AUTOSAR XML (schema 4-2-2)
package /AUTOLIV/SoftwareComponents/DIA
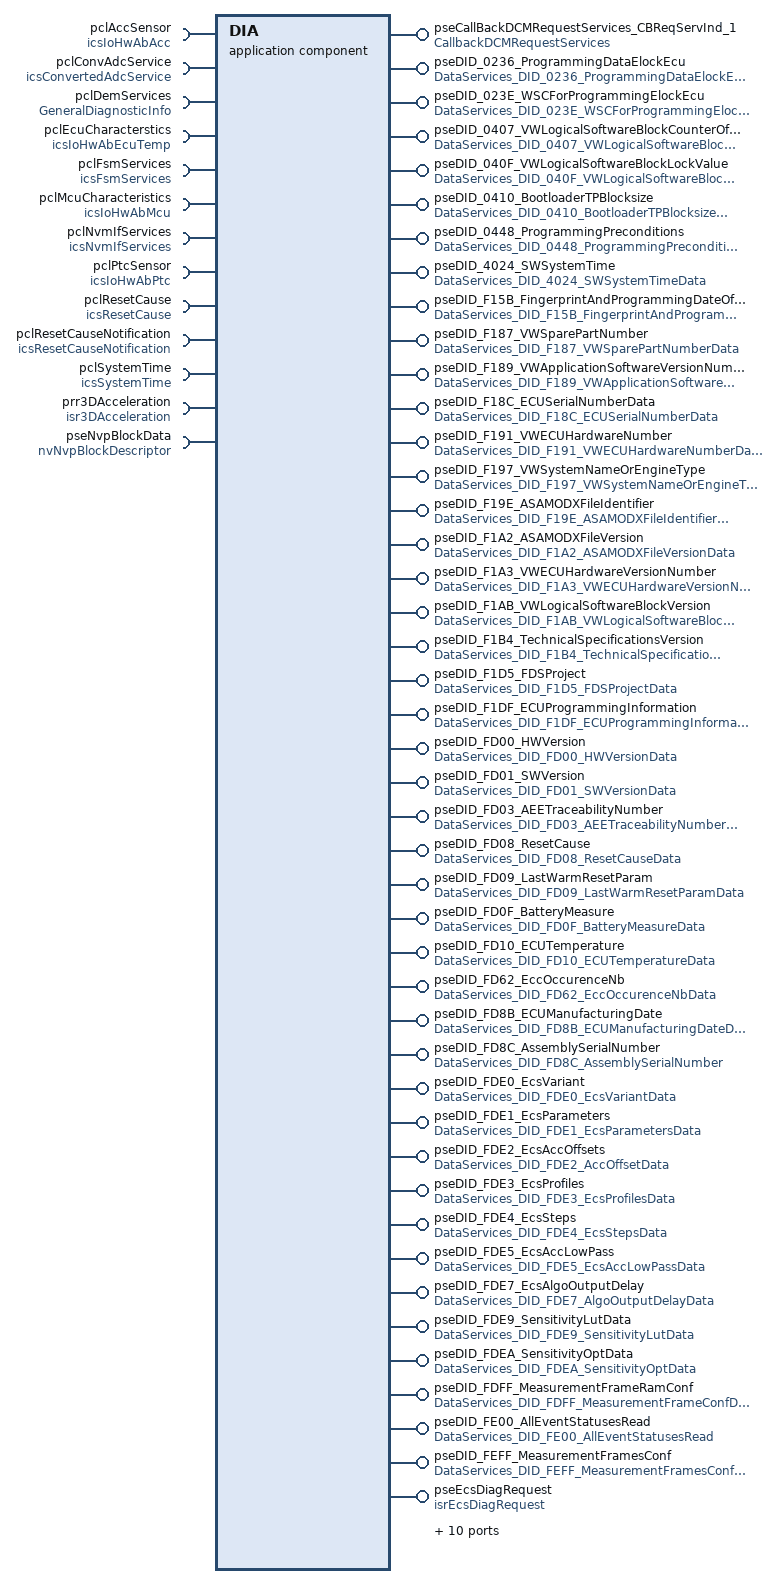
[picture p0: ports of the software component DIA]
  application sw component type DIA: category=SWC
    12 x require port:
      pclAccSensor: client-com-spec=GetTemperature, required-interface=icsIoHwAbAcc  # # Architecture Element ID ARCH_SW_DIA_pclAccSensor # Description - Interface shall be used to get the {temperature of the accelerometer in ℃}. # Data Flow ## Inputs: ## Outputs - {temperature of the accelerometer in ℃} # Linked Runnable - DIA_runRidF796_EcuTempCalibration # Traceability
      pclConvAdcService: client-com-spec=getMeasure, required-interface=icsConvertedAdcService  # # Architecture Element ID ARCH_SW_DIA_pclConvAdcService # Description - Interface shall be used to get {current value in mV} and {Mcu temperature in ℃}. # Data Flow ## Inputs: ## Outputs - {current value in mV} - {Mcu temperature in ℃} # Linked Runnable - DIA_runDid_FD0F_BatteryMeasureRead - DIA_run_DidFD10_ECUTemperatureRead # Traceability
      pclDemServices: required-interface=GeneralDiagnosticInfo  # # Architecture Element ID ARCH_SW_DIA_pclDemServices_GetEventStatus # Description - Interface used to get {the current extended event status} of a specific {event ID}. # Data Flow ## Inputs: - {event ID} ## Outputs - {the current extended event status} # Linked Runnable - DIA_runDidFE00_AllEventStatusesRead - DIA_runRid0203_CheckProgrammingPreconditions # Traceability # Architecture Element ID ARCH_SW_DIA_pclDemServices_GetEventFailed
        required-com-specs:
          GetEventStatus
          GetEventFailed
          GetEventTested
          GetDTCOfEvent
          GetFaultDetectionCounter
          GetEventFreezeFrameData
          GetEventExtendedDataRecord
          GetDebouncingOfEvent
          GetEventExtendedDataRecordEx
          GetEventFreezeFrameDataEx
      pclEcuCharacterstics: client-com-spec=GetTemperature, required-interface=icsIoHwAbEcuTemp  # # Architecture Element ID ARCH_SW_DIA_pclEcuCharacteristics # Description - Interface used to get the {Ecu temperature in ℃}. # Data Flow ## Inputs: ## Outputs - {Ecu temperature in ℃}s # Linked Runnable - DIA_run_DidFD10_ECUTemperatureRead # Traceability
      pclFsmServices: required-com-specs=[calculateProfileTimeout, getUnlockTimeoutPeriod], required-interface=icsFsmServices  # # Architecture Element ID ARCH_SW_DIA_pclFsmServices # Description - Interface shall be used to return {unlocking timeout period} of a specific {profile index}. # Data Flow ## Inputs: - {profile index} ## Outputs - {unlocking timeout period} # Linked Runnable - DIA_runDidFDE3_EcsProfilesWrite - DIA_runDidFDE4_EcsStepsWrite # Traceability
      pclMcuCharacteristics: client-com-spec=GetTemperature, required-interface=icsIoHwAbMcu  # # Architecture Element ID ARCH_SW_DIA_pclMcuCharacteristics # Description - Interface used to get the {Mcu temperature in ℃}. # Data Flow ## Inputs: ## Outputs - {Mcu temperature in ℃} # Linked Runnable - CIL_runManageMF - DIA_runRidF796_EcuTempCalibration # Traceability
      pclNvmIfServices: required-interface=icsNvmIfServices  # # Architecture Element ID ARCH_SW_DIA_pclNvmIfServices_GetNvmBlockLength # Description - Interface shall be used on event to know the {block length} of a specific {block ID}. # Data Flow ## Inputs: - {block ID} ## Outputs - {block length} # Linked Runnable - DIA_runDidFD00_HWVersionRead - DIA_runDidFEFF_MeasurementFramesConfRead - DIA_runDidFD03_AEETraceabilityNumberRead - DIA_runDidFD62_EccOccurenceNbRead - DIA_runDidFDE1_EcsParametersRead - DIA_runDidFDE2_EcsAccOffsetsRead - DIA_runDidFDE3_EcsProfilesRead - DIA_runDidFDE4_EcsStepsRead - DIA_runDidFDE5_EcsAccLowPassRead - DIA_runDIDFDE7_EcsAlgoOutputDelayRead - DIA_runDidFDE9_EcsSensitivityLutRead - DIA_runDidF187_VWSparePartNumberRead - DIA_runDidF189_VWApplicationSoftwareVersionNumberRead - DIA_runDidF191_VWECUHardwareNumberRead - DIA_runDidF197_VWSystemNameOrEngineTypeRead - DIA_runDidF1A2_ASAMODXFileVersionRead - DIA_runDidF1A3_VWECUHardwareVersionNumberRead - DIA_runDidF18C_ECUSerialNumberRead - DIA_runDidF1AB_VWLogicalSoftwareBlockVersionRead - DIA_runDidF19E_ASAMODXFileIdentifierRead - DIA_runDidFDE2_EcsAccOffsetsWrite - DIA_runDidFDE3_EcsProfilesWrite - DIA_runDidFDE4_EcsStepsWrite - DIA_runDidFDE9_EcsSensitivityLutWrite - DIA_runDidFDEA_EcsSensitivityOptWrite - DIA_runDidF189_VWApplicationSoftwareVersionNumberWrite - DIA_runDidF191_VWECUHardwareNumberWrite - DIA_runDidF197_VWSystemNameOrEngineTypeWrite - DIA_runDidF19E_ASAMODXFileIdentifierWrite - DIA_runDidF1A2_ASAMODXFileVersionWrite - DIA_runDidF18C_ECUSerialNumberWrite - DIA_runDidF1A3_VWECUHardwareVersionNumberWrite # Traceability # Architecture Element ID ARCH_SW_DIA_pclNvmIfServices_SetRamBlockStatus # Description - Interface shall be used to set the {status of a RAM block} of a specific {block ID}. # Data Flow ## Inputs: - {block ID} ## Outputs - {status of a RAM block} # Linked Runnable - DIA_runRidF796_EcuTempCalibration # Traceability # Architecture Element ID ARCH_SW_DIA_pclNvmIfServices_WriteNvmBlock # Description - Interface shall be used to write an Nvm block of a specific {block ID}. # Data Flow ## Inputs: - {block ID} ## Outputs - {Block Changed} # Linked Runnable - DIA_ManageNVPBlockWriting # Traceability # Architecture Element ID ARCH_SW_DIA_pclNvmIfServices_GetNvmBlockStatus # Description - Interface shall be used to set the {status of block} of a specific {block ID}. # Data Flow ## Inputs: - {block ID} ## Outputs - {status of block} # Linked Runnable - DIA_ManageNVPBlockWriting # Traceability
        required-com-specs:
          GetNvmBlockLength
          GetNvmBlockStatus
          ReadBlockByAddress
          RestorePRAMBlockDefaults
          SetRamBlockStatus
          WriteBlockByAddress
          WriteNvmBlock
      pclPtcSensor: client-com-spec=GetTemperature, required-interface=icsIoHwAbPtc  # # Architecture Element ID ARCH_SW_DIA_pclPtcSensor # Description - Interface used to get the {temperature of the resistor sensor in ℃}. # Data Flow ## Inputs: ## Outputs - {temperature of the resistor sensor in ℃} # Linked Runnable - DIA_runRidF796_EcuTempCalibration # Traceability
      pclResetCause: client-com-spec=GetResetCause, required-interface=icsResetCause  # # Architecture Element ID ARCH_SW_DIA_pclResetCause # Description - Interface shall be used to read the {last reset cause}. # Data Flow ## Inputs: ## Outputs - {last reset cause} # Linked Runnable - DIA_runDidFD08_ResetCauseRead # Traceability
      pclResetCauseNotification: client-com-spec=NotifyResetCause, required-interface=icsResetCauseNotification  # # Architecture Element ID ARCH_SW_DIA_pclResetCauseNotification # Description - Interface shall be used to notify DIA about the {reset cause} from RCM. # Data Flow ## Inputs: ## Outputs - {reset cause} # Linked Runnable - DIA_runDidFD08_ResetCauseRead # Traceability
      pclSystemTime: client-com-spec=ReadAbsoluteSystemTime, required-interface=icsSystemTime  # # Architecture Element ID ARCH_SW_DIA_pclSystemTime_ReadAbsoluteSystemTime # Description - Interface shall be used to read {absolute system time}. - {absolute system time} shall have 4 bytes of data + 1 byte reserved. # Data Flow ## Inputs: ## Outputs - {absolute system time} # Linked Runnable - DIA_runDid4024_SWSystemTimeRead # Traceability
      prr3DAcceleration: nonqueued-receiver-com-spec{data-element=st3DAccel, init-value=fields=[0, 0, 0]}, required-interface=isr3DAcceleration  # # Architecture Element ID ARCH_SW_prr3DAcceleration # Description - Interface shall be used to get {raw acceleration in G to CAN}. # Data Flow ## Inputs: ## Outputs - {raw acceleration in G to CAN} # Linked Runnable - DIA_runRidF794_AccCalibStart # Traceability
    44 x provide port:
      pseCallBackDCMRequestServices_CBReqServInd_1: provided-com-specs=[{operation=StartProtocol, queue-length=1}, {operation=StopProtocol, queue-length=1}], provided-interface=CallbackDCMRequestServices  # # Architecture Element ID ARCH_SW_DIA_pseCallBackDCMRequestServices_CBReqServInd_1 # Description - Interface shall be used to ask about prioritization of Diagnsotic Protocols to the Application. # Data Flow ## Inputs: - {protocol ID} ## Outputs # Linked Runnable - DIA_runCallBackDCMRequestServices_CBReqServInd_1_StartProtocol - DIA_runRte_Call_Dcm_CallBackDCMRequestServices_CBReqServInd_1_StopProtocol # Traceability
      pseDID_0236_ProgrammingDataElockEcu: provided-com-specs=[{operation=ReadData, queue-length=1}, {operation=WriteData, queue-length=1}], provided-interface=DataServices_DID_0236_ProgrammingDataElockEcuData  # # Architecture Element ID ARCH_SW_DIA_pseDID_0236_ProgrammingDataElockEcu_ReadData # Description - Interface shall be used to read {ECS parameters} from NVM and to save it in the {diagnostic buffer}. - The data content shall have 58 bytes ({ECS parameters} shall have 33 bytes + 26 bytes reserved). # Data Flow ## Inputs: - {ECS parameters} ## Outputs - {diagnostic buffer} # Linked Runnable - DIA_run_Did0236_ProgrammingDataElockEcuRead # Traceability DOM_eCS_TF_E_2130;DOM_eCS_TF_E_2133;DOM_eCS_TF_E_2134;DOM_eCS_TF_E_2135;DOM_eCS_TF_E_2136;DOM_eCS_TF_E_2137;DOM_eCS_TF_E_2137;DOM_eCS_TF_E_2138;DOM_eCS_TF_E_2139;DOM_eCS_TF_E_2140;DOM_eCS_TF_E_2141;DOM_eCS_TF_E_2142;DOM_eCS_TF_E_2143;DOM_eCS_TF_E_2144;DOM_eCS_TF_E_2145;DOM_eCS_TF_E_2146;DOM_eCS_TF_E_2147;DOM_eCS_TF_E_2148;DOM_eCS_TF_E_2149;DOM_eCS_TF_E_2150;DOM_eCS_TF_E_2151;DOM_eCS_TF_E_2152; DOM_eCS_TF_E_2153;DOM_eCS_TF_E_2154 # Architecture Element ID ARCH_SW_DIA_pseDID_0236_ProgrammingDataElockEcu_WriteData # Description - Interface shall be used to write the {diagnostic buffer} value in the NVP variables which store the {ECS parameters}. - The data content shall have 58 bytes ({ECS parameters} shall have 33 bytes + 26 bytes reserved). - Interface shall return {ErrorCode} 0x72 if the write operation failed. # Data Flow ## Inputs: - {diagnostic buffer} ## Outputs - {ECS parameters} # Linked Runnable - DIA_run_Did0236_ProgrammingDataElockEcuWrite # Traceability DOM_eCS_TF_E_2160;DOM_eCS_TF_E_2164;DOM_eCS_TF_E_2182;DOM_eCS_TF_E_2183;DOM_eCS_TF_E_2184;DOM_eCS_TF_E_2185;DOM_eCS_TF_E_2186;DOM_eCS_TF_E_2187;DOM_eCS_TF_E_2188;DOM_eCS_TF_E_2189;DOM_eCS_TF_E_2190;DOM_eCS_TF_E_2191;DOM_eCS_TF_E_2192;DOM_eCS_TF_E_2193;DOM_eCS_TF_E_2194;DOM_eCS_TF_E_2195;DOM_eCS_TF_E_2196;DOM_eCS_TF_E_2197;DOM_eCS_TF_E_2198;DOM_eCS_TF_E_2199;DOM_eCS_TF_E_2200;DOM_eCS_TF_E_2201;DOM_eCS_TF_E_2202;DOM_eCS_TF_E_2168
      pseDID_023E_WSCForProgrammingElockEcu: provided-com-specs=[{operation=ReadData, queue-length=1}, {operation=WriteData, queue-length=1}], provided-interface=DataServices_DID_023E_WSCForProgrammingElockEcuData  # # Architecture Element ID ARCH_SW_DIA_pseDID_023E_WSCForProgrammingElockEcu_ReadData # Description - Interface shall be used to read {ECS variant} from NVM and to save it in the {diagnostic buffer}. - The data content shall have 6 bytes ({ECS variant} shall have 4 bytes + 2 bytes reserved). # Data Flow ## Inputs: - {ECS variant} ## Outputs - {diagnostic buffer} # Linked Runnable - DIA_run_Did023E_WSCForProgrammingElockEcuRead # Traceability DOM_eCS_TF_E_2117;DOM_eCS_TF_E_2155 # Architecture Element ID ARCH_SW_DIA_pseDID_023E_WSCForProgrammingElockEcu_WriteData # Description - Interface shall be used to write the {diagnostic buffer} value in the NVP variable which stores the {ECS variant}. - The data content shall have 6 bytes ({ECS variant} shall have 4 bytes + 2 bytes reserved). - Interface shall return {ErrorCode} 0x72 if the write operation failed. # Data Flow ## Inputs: - {diagnostic buffer} ## Outputs - {ECS variant} # Linked Runnable - DIA_run_Did023E_WSCForProgrammingElockEcuWrite # Traceability DOM_eCS_TF_E_2176;DOM_eCS_TF_E_2177;DOM_eCS_TF_E_2181
      pseDID_0407_VWLogicalSoftwareBlockCounterOfProgrammingAttempts: server-com-spec{operation=ReadData, queue-length=1}, provided-interface=DataServices_DID_0407_VWLogicalSoftwareBlockCounterOfProgrammingAttemptsData  # # Architecture Element ID ARCH_SW_DIA_pseDID_0407_VWLogicalSoftwareBlockCounterOfProgrammingAttempts # Description - Interface shall be used to read {Ecu serial number} from NVM and to save it in the {diagnostic buffer}. # Data Flow ## Inputs: - {Ecu serial number} ## Outputs - {diagnostic buffer} # Linked Runnable - DIA_runDid0407_VWLogicalSoftwareBlockCounterOfProgrammingAttemptsRead # Traceability DOM_eCS_TF_E_1457; DOM_eCS_TF_E_1463; DOM_eCS_TF_E_1464
      pseDID_040F_VWLogicalSoftwareBlockLockValue: server-com-spec{operation=ReadData, queue-length=1}, provided-interface=DataServices_DID_040F_VWLogicalSoftwareBlockLockValueData  # # Architecture Element ID ARCH_SW_DIA_pseDID_040F_VWLogicalSoftwareBlockLockValue # Description - Interface shall be used to read {VW Logical Software Block Lock} value and to save it in the {diagnostic buffer}. - {VW Logical Software Block Lock} shall have 6 bytes. # Data Flow ## Inputs: - {VW Logical Software Block Lock} ## Outputs - {diagnostic buffer} # Linked Runnable - DIA_runDid040F_VWLogicalSoftwareBlockLockValueRead # Traceability DOM_eCS_TF_E_128; DOM_eCS_TF_E_1473; DOM_eCS_TF_E_1474; DOM_eCS_TF_E_1475
      pseDID_0410_BootloaderTPBlocksize: provided-com-specs=[{operation=ReadData, queue-length=1}, {operation=WriteData, queue-length=1}], provided-interface=DataServices_DID_0410_BootloaderTPBlocksizeData  # # Architecture Element ID ARCH_SW_DIA_pseDID_0410_BootloaderTPBlocksize_ReadData # Description - Interface shall be used to read {Bootloader TP block size} value and to save it in the {diagnostic buffer}. - {Bootloader TP block size} shall have 1 byte. # Data Flow ## Inputs: - {Bootloader TP block size} ## Outputs - {diagnostic buffer} # Linked Runnable - DIA_runDid0410_BootloaderTPBlocksizeRead # Traceability DOM_eCS_TF_E_128;DOM_eCS_TF_E_1492;DOM_eCS_TF_E_1946 # Architecture Element ID ARCH_SW_DIA_pseDID_0410_BootloaderTPBlocksize_WriteData # Description - Interface shall be used to write the {diagnostic buffer} value in the variable which stores the {Bootloader TP block size}. - {Bootloader TP block size} shall have 1 byte. # Data Flow ## Inputs: - {diagnostic buffer} ## Outputs - {Bootloader TP block size} # Linked Runnable - DIA_runDid0410_BootloaderTPBlocksizeWrite # Traceability DOM_eCS_TF_E_633; DOM_eCS_TF_E_635
      pseDID_0448_ProgrammingPreconditions: server-com-spec{operation=ReadData, queue-length=1}, provided-interface=DataServices_DID_0448_ProgrammingPreconditionsData  # # Architecture Element ID ARCH_SW_DIA_pseDID_0448_ProgrammingPreconditions # Description - Interface shall be used to read the {programming preconditions} value and to save it in the {diagnostic buffer}. # Data Flow ## Inputs: - {programming preconditions} ## Outputs - {diagnostic buffer} # Linked Runnable - DIA_runDid0448_ProgrammingPreconditionsRead # Traceability DOM_eCS_TF_E_1501;DOM_eCS_TF_E_1505;DOM_eCS_TF_E_1506;DOM_eCS_TF_E_1507;DOM_eCS_TF_E_1509
      pseDID_4024_SWSystemTime: server-com-spec{operation=ReadData, queue-length=1}, provided-interface=DataServices_DID_4024_SWSystemTimeData  # # Architecture Element ID ARCH_SW_DIA_pseDID_4024_SWSystemTime # Description - Interface shall be used to read the {absolute system time} value and to save it in the {diagnostic buffer}. - {absolute system time} shall have 5 bytes (4 bytes of data + 1 byte reserved). # Data Flow ## Inputs: - {absolute system time} ## Outputs - {diagnostic buffer} # Linked Runnable - DIA_runDid4024_SWSystemTimeRead # Traceability DOM_eCS_TF_E_183;DOM_eCS_TF_E_1520;DOM_eCS_TF_E_1524;DOM_eCS_TF_E_1525;DOM_eCS_TF_E_1527
      pseDID_F15B_FingerprintAndProgrammingDateOfLogicalSoftwareBlocks: server-com-spec{operation=ReadData, queue-length=1}, provided-interface=DataServices_DID_F15B_FingerprintAndProgrammingDateOfLogicalSoftwareBlocksData  # # Architecture Element ID ARCH_SW_DIA_pseDID_F15B_FingerprintAndProgrammingDateOfLogicalSoftwareBlocks # Description - Interface shall be used to read the {fingerprint and programming date of logical SW blocks} from NVM and to save it in the {diagnostic buffer}. - {fingerprint and programming date of logical SW blocks} shall have 30 bytes. # Data Flow ## Inputs: - {fingerprint and programming date of logical SW blocks} ## Outputs - {diagnostic buffer} # Linked Runnable - DIA_runDidF15B_FingerprintAndProgrammingDateOfLogicalSoftwareBlocksRead # Traceability
      pseDID_F187_VWSparePartNumber: provided-com-specs=[{operation=ReadData, queue-length=1}, {operation=WriteData, queue-length=1}], provided-interface=DataServices_DID_F187_VWSparePartNumberData  # # Architecture Element ID ARCH_SW_DIA_pseDID_F187_VWSparePartNumber_ReadData # Description - Interface shall be used to read {Spare Part Number} from NVM and to save it in the {diagnostic buffer}. - {Spare Part Number} shall have 11 bytes. # Data Flow ## Inputs: - {Spare Part Number} ## Outputs - {diagnostic buffer} # Linked Runnable - DIA_runDidF187_VWSparePartNumberRead # Traceability DOM_eCS_TF_E_1548;DOM_eCS_TF_E_1552 # Architecture Element ID ARCH_SW_DIA_pseDID_F187_VWSparePartNumber_WriteData # Description - Interface shall be used to write the {diagnostic buffer} value in the NVP variable which stores the {Spare Part Number}. - Interface shall return {ErrorCode} 0x22 if Ecu is locked. - Interface shall return {ErrorCode} 0x72 if the write operation failed. - Interface shall return {ErrorCode} 0x31 if the written values are not in ASCII codes interval. - {Spare Part Number} shall have 11 bytes. # Data Flow ## Inputs: - {diagnostic buffer} ## Outputs - {Spare Part Number} # Linked Runnable - DIA_runDidF187_VWSparePartNumberWrite # Traceability DOM_eCS_TF_E_1709;DOM_eCS_TF_E_1906;DOM_eCS_TF_E_1710;DOM_eCS_TF_E_1951;DOM_eCS_TF_E_1713;DOM_eCS_TF_E_1950
      pseDID_F189_VWApplicationSoftwareVersionNumber: provided-com-specs=[{operation=ReadData, queue-length=1}, {operation=WriteData, queue-length=1}], provided-interface=DataServices_DID_F189_VWApplicationSoftwareVersionNumberData  # # Architecture Element ID ARCH_SW_DIA_pseDID_F189_VWApplicationSoftwareVersionNumber_ReadData # Description - Interface shall be used to read {VW Application SW Version Number} from NVM and to save it in the {diagnostic buffer}. - {VW Application SW Version Number} shall have 4 bytes. # Data Flow ## Inputs: - {VW Application SW Version Number} ## Outputs - {diagnostic buffer} # Linked Runnable - DIA_runDidF189_VWApplicationSoftwareVersionNumberRead # Traceability DOM_eCS_TF_E_128;DOM_eCS_TF_E_115;DOM_eCS_TF_E_1575 # Architecture Element ID ARCH_SW_DIA_pseDID_F189_VWApplicationSoftwareVersionNumber_WriteData # Description - Interface shall be used to write the {diagnostic buffer} value in the NVP variable which stores the {VW Application SW Version Number}. - Interface shall return {ErrorCode} 0x22 if Ecu is locked. - Interface shall return {ErrorCode} 0x72 if the write operation failed. - {VW Application SW Version Number} shall have 4 bytes. # Data Flow ## Inputs: - {diagnostic buffer} ## Outputs - {VW Application SW Version Number} - {ErrorCode} # Linked Runnable - DIA_runDidF189_VWApplicationSoftwareVersionNumberWrite # Traceability DOM_eCS_TF_E_1952;DOM_eCS_TF_E_628;DOM_eCS_TF_E_1954;DOM_eCS_TF_E_622
      pseDID_F18C_ECUSerialNumberData: provided-com-specs=[{operation=ReadData, queue-length=1}, {operation=WriteData, queue-length=1}], provided-interface=DataServices_DID_F18C_ECUSerialNumberData  # # Architecture Element ID ARCH_SW_DIA_pseDID_F18C_ECUSerialNumberData_ReadData # Description - Interface shall be used to read {Ecu serial number} from NVM and to save it in the {diagnostic buffer}. - {Ecu serial number} shall have 20 bytes. # Data Flow ## Inputs: - {Ecu serial number} ## Outputs - {diagnostic buffer} # Linked Runnable - DIA_runDidF18C_ECUSerialNumberRead # Traceability DOM_eCS_TF_E_1561; DOM_eCS_TF_E_1562 # Architecture Element ID ARCH_SW_DIA_pseDID_F18C_ECUSerialNumberData_WriteData # Description - Interface shall be used to write the {diagnostic buffer} value in the NVP variable which stores the {Ecu serial number}. - {Ecu serial number} shall have 20 bytes. - Interface shall return {ErrorCode} 0x22 if Ecu is locked. - Interface shall return {ErrorCode} 0x72 if the write operation failed. - Interface shall return {ErrorCode} 0x31 if the written values are not in ASCII codes interval. # Data Flow ## Inputs: - {diagnostic buffer} ## Outputs - {Ecu serial number} # Linked Runnable - DIA_runDidF18C_ECUSerialNumberWrite # Traceability DOM_eCS_TF_E_1765;DOM_eCS_TF_E_1766;DOM_eCS_TF_E_1912;DOM_eCS_TF_E_1961;DOM_eCS_TF_E_1769;DOM_eCS_TF_E_1963;
      pseDID_F191_VWECUHardwareNumber: provided-com-specs=[{operation=ReadData, queue-length=1}, {operation=WriteData, queue-length=1}], provided-interface=DataServices_DID_F191_VWECUHardwareNumberData  # # Architecture Element ID ARCH_SW_DIA_pseDID_F191_VWECUHardwareNumber_ReadData # Description - Interface shall be used to read {Ecu Hardware Number} and to save it in the {diagnostic buffer}. - {Ecu Hardware Number} shall have 11 bytes. # Data Flow ## Inputs: - {Ecu Hardware Number} ## Outputs - {diagnostic buffer} # Linked Runnable - DIA_runDidF191_VWECUHardwareNumberRead # Traceability DOM_eCS_TF_E_1587;DOM_eCS_TF_E_1588 # Architecture Element ID ARCH_SW_DIA_pseDID_F191_VWECUHardwareNumber_WriteData # Description - Interface shall be used to write the {diagnostic buffer} value in the NVP variable which stores the {Ecu Hardware Number}. - Interface shall return {ErrorCode} 0x22 if Ecu is locked. - Interface shall return {ErrorCode} 0x72 if the write operation failed. - Interface shall return {ErrorCode} 0x31 if the written values are not in ASCII codes interval. - {Ecu Hardware Number} shall have 11 bytes. # Data Flow ## Inputs: - {diagnostic buffer} ## Outputs - {Ecu Hardware Number} # Linked Runnable - DIA_runDidF191_VWECUHardwareNumberWrite # Traceability DOM_eCS_TF_E_1737;DOM_eCS_TF_E_1738;DOM_eCS_TF_E_1908;DOM_eCS_TF_E_1955;DOM_eCS_TF_E_1741;DOM_eCS_TF_E_1957
      pseDID_F197_VWSystemNameOrEngineType: provided-com-specs=[{operation=ReadData, queue-length=1}, {operation=WriteData, queue-length=1}], provided-interface=DataServices_DID_F197_VWSystemNameOrEngineTypeData  # # Architecture Element ID ARCH_SW_DIA_pseDID_F197_VWSystemNameOrEngineType_ReadData # Description - Interface shall be used to read the {VW system name} value from NVM and to save it in the {diagnostic buffer}. - {VW system name} shall have 13 bytes. # Data Flow ## Inputs: - {VW system name} ## Outputs - {diagnostic buffer} # Linked Runnable - DIA_runDidF197_VWSystemNameOrEngineTypeRead # Traceability DOM_eCS_TF_E_1600;DOM_eCS_TF_E_1601;DOM_eCS_TF_E_1910;DOM_eCS_TF_E_1751;DOM_eCS_TF_E_1752;DOM_eCS_TF_E_1958;DOM_eCS_TF_E_1755;DOM_eCS_TF_E_1960 ---------------------------------------------------------------------------------------------- # Architecture Element ID ARCH_SW_DIA_pseDID_F197_VWSystemNameOrEngineType_WriteData # Description - Interface shall be used to write the {diagnostic buffer} value in NVP variable which stores the {VW system name}. - Interface shall return {ErrorCode} 0x22 if Ecu is locked. - Interface shall return {ErrorCode} 0x72 if the write operation failed. - Interface shall return {ErrorCode} 0x31 if the written values are not in ASCII codes interval. - {VW system name} shall have 13 bytes. # Data Flow ## Inputs: - {diagnostic buffer} ## Outputs - {VW system name} # Linked Runnable - DIA_runDidF197_VWSystemNameOrEngineTypeWrite # Traceability DOM_eCS_TF_E_1751;DOM_eCS_TF_E_1752;DOM_eCS_TF_E_1910;DOM_eCS_TF_E_1958;DOM_eCS_TF_E_1755;DOM_eCS_TF_E_1960
      pseDID_F19E_ASAMODXFileIdentifier: provided-com-specs=[{operation=ReadData, queue-length=1}, {operation=WriteData, queue-length=1}], provided-interface=DataServices_DID_F19E_ASAMODXFileIdentifierData  # # Architecture Element ID ARCH_SW_DIA_pseDID_F19E_ASAMODXFileIdentifier_ReadData # Description - Interface shall be used to read the {ASAM ODX file identifier} from NVM value and to save it in the {diagnostic buffer}. - {ASAM ODX file identifier} shall have 24 bytes. # Data Flow ## Inputs: - {ASAM ODX file identifier} ## Outputs - {diagnostic buffer} # Linked Runnable - DIA_runDidF19E_ASAMODXFileIdentifierRead # Traceability - DOM_eCS_TF_E_1616 # Architecture Element ID ARCH_SW_DIA_pseDID_F19E_ASAMODXFileIdentifier_WriteData # Description - Interface shall be used to write the {diagnostic bufer} value in the NVP variable which stores the {ASAM ODX file identifier}. - Interface shall return {ErrorCode} 0x22 if Ecu is locked. - Interface shall return {ErrorCode} 0x72 if the write operation failed. - Interface shall return {ErrorCode} 0x31 if the written values are not in ASCII codes interval. - {ASAM ODX file identifier} configuration shall have 24 bytes. # Data Flow ## Inputs: - {diagnostic buffer} ## Outputs - {ASAM ODX file identifier} # Linked Runnable - DIA_runDidF19E_ASAMODXFileIdentifierWrite # Traceability DOM_eCS_TF_E_2061;DOM_eCS_TF_E_2071;DOM_eCS_TF_E_2064;DOM_eCS_TF_E_2065;DOM_eCS_TF_E_2067
      pseDID_F1A2_ASAMODXFileVersion: provided-com-specs=[{operation=ReadData, queue-length=1}, {operation=WriteData, queue-length=1}], provided-interface=DataServices_DID_F1A2_ASAMODXFileVersionData  # # Architecture Element ID ARCH_SW_DIA_pseDID_F1A2_ASAMODXFileVersion_ReadData # Description - Interface shall be used to read the {ASAM ODX file version} from NVM and to save the value in the {diagnostic buffer}. # Data Flow ## Inputs: - {ASAM ODX file version} ## Outputs - {diagnostic buffer} # Linked Runnable - DIA_runDidF1A2_ASAMODXFileVersionRead # Traceability DOM_eCS_TF_E_1625;DOM_eCS_TF_E_1626 # Architecture Element ID ARCH_SW_DIA_pseDID_F1A2_ASAMODXFileVersion_WriteData # Description - Interface shall be used to write the {diagnostic buffer} value in NVP variable which stores the {ASAM ODX file version}. - Interface shall return {ErrorCode} 0x22 if Ecu is locked. - Interface shall return {ErrorCode} 0x72 if the write operation failed. # Data Flow ## Inputs: - {diagnostic buffer} ## Outputs - {ASAM ODX file version} - {ErrorCode} # Linked Runnable - DIA_runDidF1A2_ASAMODXFileVersionWrite # Traceability
      pseDID_F1A3_VWECUHardwareVersionNumber: provided-com-specs=[{operation=ReadData, queue-length=1}, {operation=WriteData, queue-length=1}], provided-interface=DataServices_DID_F1A3_VWECUHardwareVersionNumberData  # # Architecture Element ID ARCH_SW_DIA_pseDID_F1A3_VWECUHardwareVersionNumber_ReadData # Description - Interface shall be used to read the {Ecu hardware version number} from NVM value and to save it in the {diagnostic buffer}. - {Ecu hardware version number} shall have 3 bytes. # Data Flow ## Inputs: - {Ecu hardware version number} ## Outputs - {diagnostic buffer} # Linked Runnable - DIA_runDidF1A3_VWECUHardwareVersionNumberRead # Traceability DOM_eCS_TF_E_1638;DOM_eCS_TF_E_1639 # Architecture Element ID ARCH_SW_DIA_pseDID_F1A3_VWECUHardwareVersionNumber_WriteData # Description - Interface shall be used to write the {diagnostic bufer} value in the NVP variable which stores the {Ecu hardware version number}. - Interface shall return {ErrorCode} 0x22 if Ecu is locked. - Interface shall return {ErrorCode} 0x72 if the write operation failed. - {Ecu hardware version number} configuration shall have 3 bytes. # Data Flow ## Inputs: - {diagnostic buffer} ## Outputs - {Ecu hardware version number} # Linked Runnable - DIA_runDidF1A3_VWECUHardwareVersionNumberWrite # Traceability DOM_eCS_TF_E_1723;DOM_eCS_TF_E_1724;DOM_eCS_TF_E_1914;DOM_eCS_TF_E_1964;DOM_eCS_TF_E_1727;DOM_eCS_TF_E_1966
      pseDID_F1AB_VWLogicalSoftwareBlockVersion: server-com-spec{operation=ReadData, queue-length=1}, provided-interface=DataServices_DID_F1AB_VWLogicalSoftwareBlockVersionData  # # Architecture Element ID ARCH_SW_DIA_pseDID_F1AB_VWLogicalSoftwareBlockVersion # Description - Interface shall be used to read {VW Logical SW Block Version} from NVM and to save it in the {diagnostic buffer}. - {Hardware Version Number} shall have 12 bytes. # Data Flow ## Inputs: - {VW Logical SW Block Version} ## Outputs - {diagnostic buffer} # Linked Runnable - DIA_runDidF1AB_VWLogicalSoftwareBlockVersionRead # Traceability DOM_eCS_TF_E_1654;DOM_eCS_TF_E_1655;DOM_eCS_TF_E_1656
      pseDID_F1B4_TechnicalSpecificationsVersion: server-com-spec{operation=ReadData, queue-length=1}, provided-interface=DataServices_DID_F1B4_TechnicalSpecificationsVersionData  # # Architecture Element ID ARCH_SW_DIA_pseDID_F1B4_TechnicalSpecificationsVersion # Description - Interface shall be used to read {Technical Specification version} and to save it in the {diagnostic buffer}. - {Technical Specification version} shall have 26 bytes. # Data Flow ## Inputs: - {Technical Specification version} ## Outputs - {diagnostic buffer} # Linked Runnable - DIA_runDidF1B4_TechnicalSpecificationsVersionRead # Traceability DOM_eCS_TF_E_1666;DOM_eCS_TF_E_1667
      pseDID_F1D5_FDSProject: server-com-spec{operation=ReadData, queue-length=1}, provided-interface=DataServices_DID_F1D5_FDSProjectData  # # Architecture Element ID ARCH_SW_DIA_pseDID_F1D5_FDSProject # Description - Interface shall be used to read the {FDS project parameters} value and to save it in the {diagnostic buffer}. # Data Flow ## Inputs: - {FDS project parameters} ## Outputs - {diagnostic buffer} # Linked Runnable - DIA_runDidF1D5_FDSProjectDataRead # Traceability DOM_eCS_TF_E_1679;DOM_eCS_TF_E_1680;DOM_eCS_TF_E_1681
      pseDID_F1DF_ECUProgrammingInformation: server-com-spec{operation=ReadData, queue-length=1}, provided-interface=DataServices_DID_F1DF_ECUProgrammingInformationData  # # Architecture Element ID ARCH_SW_DIA_pseDID_F1DF_ECUProgrammingInformation # Description - Interface shall be used to read the {DID information} according to the {Diagnostic Service Identifier}. - Interface shall return {Error Code} 0x31 if {Diagnostic Service Identifier} is not valid. # Data Flow ## Inputs: - {Diagnostic Service Identifier} ## Outputs - {DID information} - {Error Code} # Linked Runnable - UDS_ReadDataByIdentifier # Traceability DOM_eCS_TF_E_1696
      pseDID_FD00_HWVersion: provided-com-specs=[{operation=ReadData, queue-length=1}, {operation=WriteData, queue-length=1}], provided-interface=DataServices_DID_FD00_HWVersionData  # # Architecture Element ID ARCH_SW_DIA_pseDID_FD00_HWVersion_ReadData # Description - Interface shall be used to read the {Hardware Version Number} from NVM and to save it in the {diagnostic buffer}. - {Hardware Version Number} shall have 10 bytes. # Data Flow ## Inputs: - {Hardware Version Number} ## Outputs - {diagnostic buffer} # Linked Runnable - DIA_runDidFD00_HWVersionRead # Traceability DOM_eCS_TF_E_128 # Architecture Element ID ARCH_SW_DIA_pseDID_FD00_HWVersion_WriteData # Description - Interface shall be used to write the {diagnostic buffer} value in the NVP variable which stores the {Hardware Version Number}. - Interface shall return {ErrorCode} 0x22 if Ecu is locked. - Interface shall return {ErrorCode} 0x72 if the write operation failed. - {Hardware Version Number} shall have 10 bytes. # Data Flow ## Inputs: - {diagnostic buffer} ## Outputs - {Hardware Version Number} # Linked Runnable - DIA_runDidFD00_HWVersionWrite # Traceability DOM_eCS_TF_E_633; DOM_eCS_TF_E_635;DOM_eCS_TF_E_1967;DOM_eCS_TF_E_1969
      pseDID_FD01_SWVersion: server-com-spec{operation=ReadData, queue-length=1}, provided-interface=DataServices_DID_FD01_SWVersionData  # # Architecture Element ID ARCH_SW_DIA_pseDID_FD01_SWVersion # Description - Interface shall be used to read the {SW version number} and to save it in the {diagnostic buffer} # Data Flow ## Inputs: - {SW version number} ## Outputs - {diagnostic buffer} # Linked Runnable - DIA_runDidFD01_SWVersionRead # Traceability DOM_eCS_TF_E_146
      pseDID_FD03_AEETraceabilityNumber: provided-com-specs=[{operation=ReadData, queue-length=1}, {operation=WriteData, queue-length=1}], provided-interface=DataServices_DID_FD03_AEETraceabilityNumberData  # # Architecture Element ID ARCH_SW_DIA_pseDID_FD03_AEETraceabilityNumberRead # Description - Interface shall be used to read the {AEE traceability number} value from NVM and to save it in the {diagnostic buffer}. - {AEE traceability number} shall have 12 bytes. # Data Flow ## Inputs: - {AEE traceability number} ## Outputs - {diagnostic buffer} # Linked Runnable - DIA_runDidFD03_AEETraceabilityNumberRead # Traceability DOM_eCS_TF_E_196 # Architecture Element ID ARCH_SW_DIA_pseDID_FD03_AEETraceabilityNumberWrite # Description - Interface shall be used to write the {diagnostic buffer} value in the NVP variable which stores the {AEE traceability number}. - Interface shall return {ErrorCode} 0x22 if Ecu is locked. - Interface shall return {ErrorCode} 0x72 if the write operation failed. - {AEE Traceability Number} shall have 12 bytes. # Data Flow ## Inputs: - {diagnostic buffer} ## Outputs - {AEE traceability Number} # Linked Runnable - DIA_runDidFD03_AEETraceabilityNumberWrite #Traceability DOM_eCS_TF_E_2076;DOM_eCS_TF_E_2080;DOM_eCS_TF_E_2083;DOM_eCS_TF_E_2084;DOM_eCS_TF_E_2086
      pseDID_FD08_ResetCause: server-com-spec{operation=ReadData, queue-length=1}, provided-interface=DataServices_DID_FD08_ResetCauseData  # # Architecture Element ID ARCH_SW_DIA_pseDID_FD08_ResetCause # Description - Interface shall be used to read {last reset cause} and to save it in the {diagnostic buffer}. # Data Flow ## Inputs: - {last reset cause} ## Outputs - {diagnostic buffer} # Linked Runnable - DIA_runDidFD08_ResetCauseRead # Traceability DOM_eCS_TF_E_253;
      pseDID_FD09_LastWarmResetParam: server-com-spec{operation=ReadData, queue-length=1}, provided-interface=DataServices_DID_FD09_LastWarmResetParamData  # # Architecture Element ID ARCH_SW_DIA_pseDID_FD09_LastWarmResetParam # Description - Interface shall be used to read {last warm reset} value from NVM and to save it in the {diagnostic buffer}. - {last warm reset} shall have 4 bytes. # Data Flow ## Inputs: - {last warm reset} ## Outputs - {diagnostic buffer} # Linked Runnable - DIA_runDidFD09_LastWarmResetParamRead # Traceability DOM_eCS_TF_E_231; DOM_eCS_TF_E_232;
      pseDID_FD0F_BatteryMeasure: server-com-spec{operation=ReadData, queue-length=1}, provided-interface=DataServices_DID_FD0F_BatteryMeasureData  # # Architecture Element ID ARCH_SW_DIA_pseDID_FD0F_BatteryMeasure # Description - Interface shall be used to read the {Battery Measure in mV} and to save it in the {diagnostic buffer}. # Data Flow ## Inputs: - {Battery Measure in mV} ## Outputs - {diagnostic buffer} # Linked Runnable - DIA_runDid_FD0F_BatteryMeasureRead # Traceability DOM_eCS_TF_E_296
      pseDID_FD10_ECUTemperature: server-com-spec{operation=ReadData, queue-length=1}, provided-interface=DataServices_DID_FD10_ECUTemperatureData  # # Architecture Element ID ARCH_SW_DIA_pseDID_FD10_MCUTemperature # Description - Interface shall be used to read {MCU Temperature} and to save it in the {diagnostic buffer}. - {MCU Temperature} shall have 2 bytes. # Data Flow ## Inputs: - {MCU Temperature} ## Outputs - {diagnostic buffer} # Linked Runnable - DIA_run_DidFD10_MCUTemperatureRead # Traceability DOM_eCS_TF_E_305
      pseDID_FD62_EccOccurenceNb: server-com-spec{operation=ReadData, queue-length=1}, provided-interface=DataServices_DID_FD62_EccOccurenceNbData  # # Architecture Element ID ARCH_SW_DIA_pseDID_FD62_EccOccurenceNb # Description - Interface shall be used to read {number of ECCs} and to save it in the {diagnostic buffer}. - {number of ECCs} shall have 4 bytes. # Data Flow ## Inputs: - {number of ECCs} ## Outputs - {diagnostic buffer} # Linked Runnable - DIA_runDidFD62_EccOccurenceNbRead # Traceability DOM_eCS_TF_E_241; DOM_eCS_TF_E_242; DOM_eCS_TF_E_243; DOM_eCS_TF_E_244;
      pseDID_FD8B_ECUManufacturingDate: provided-com-specs=[{operation=ReadData, queue-length=1}, {operation=WriteData, queue-length=1}], provided-interface=DataServices_DID_FD8B_ECUManufacturingDateData  # # Architecture Element ID ARCH_SW_DIA_pseDID_FD8B_ECUManufacturingDateRead # Description - Interface shall be used to read the {Ecu manufacturing date} value from NVM and to save it in the {diagnostic buffer}. - {Ecu manufacturing date} shall have 3 bytes. # Data Flow ## Inputs: - {Ecu manufacturing date} ## Outputs - {diagnostic buffer} # Linked Runnable - DIA_runDidFD8B_ECUManufacturingDateRead # Traceability DOM_eCS_TF_E_216; DOM_eCS_TF_E_217; DOM_eCS_TF_E_218; # Architecture Element ID ARCH_SW_DIA_pseDID_FD8B_ECUManufacturingDateWrite # Description - Interface shall be used to write the {diagnostic bufer} value in the NVP variable which stores the {Ecu manufacturing date}. - {Ecu manufacturing date} shall have 3 bytes. # Data Flow ## Inputs: - {Ecu manufacturing date} ## Outputs - {diagnostic buffer} # Linked Runnable - DIA_runDidFD8B_ECUManufacturingDateWrite # Traceability DOM_eCS_TF_E_668;DOM_eCS_TF_E_670;DOM_eCS_TF_E_671;DOM_eCS_TF_E_672;DOM_eCS_TF_E_1972
      pseDID_FD8C_AssemblySerialNumber: provided-com-specs=[{operation=ReadData, queue-length=1}, {operation=WriteData, queue-length=1}], provided-interface=DataServices_DID_FD8C_AssemblySerialNumber  # # Architecture Element ID ARCH_SW_DIA_pseDID_FD8C_AssemblySerialNumber_ReadData # Description - Interface shall be used to read the {Ecu Assembly Serial Number} value from NVM and to save it in the {diagnostic buffer}. - {Ecu Assembly Serial Number} shall have 20 bytes. # Data Flow ## Inputs: - {Ecu Assembly Serial Number} ## Outputs - {diagnostic buffer} # Linked Runnable - DIA_runDidFD8C_AssemblySerialNumberRead # Traceability DOM_eCS_TF_E_87; # Architecture Element ID ARCH_SW_DIA_pseDID_FD8C_AssemblySerialNumber_WriteData # Description - Interface shall be used to write the {diagnostic bufer} value in the NVP variable which stores the {accelerometer lowpass filter value (x/y/z)}. - Interface shall return {ErrorCode} 0x22 if Ecu is locked. - Interface shall return {ErrorCode} 0x72 if the write operation failed. - {Ecu Assembly Serial Number} shall have 20 bytes. # Data Flow ## Inputs: - {diagnostic buffer} ## Outputs - {Ecu Assembly Serial Number} # Linked Runnable - DIA_runDidFD8C_AssemblySerialNumberWrite # Traceability DOM_eCS_TF_E_592; DOM_eCS_TF_E_594; DOM_eCS_TF_E_614;DOM_eCS_TF_E_1973;DOM_eCS_TF_E_1975
      pseDID_FDE0_EcsVariant: provided-com-specs=[{operation=ReadData, queue-length=1}, {operation=WriteData, queue-length=1}], provided-interface=DataServices_DID_FDE0_EcsVariantData  # # Architecture Element ID ARCH_SW_DIA_pseDID_FDE0_EcsVariant_ReadData # Description - Interface shall be used to read the {eCS variant} value and to save it in the {diagnostic buffer}. - {eCS variant} shall have 1 byte. # Data Flow ## Inputs: - {eCS variant} ## Outputs - {diagnostic buffer} # Linked Runnable - DIA_runDidFDE0_EcsVariantRead # Traceability DOM_eCS_TF_E_314; # Architecture Element ID ARCH_SW_DIA_pseDID_FDE0_EcsVariant_WriteData # Description - Interface shall be used to write the {diagnostic bufer} value in the variable which stores the {eCS variant}. - Interface shall return {ErrorCode} 0x22 if Ecu is locked. - Interface shall return {ErrorCode} 0x72 if the write operation failed. - {eCS variant} shall have 1 byte. # Data Flow ## Inputs: - {diagnostic buffer} ## Outputs - {eCS variant} # Linked Runnable - DIA_runDidFDE0_EcsVariantWrite # Traceability DOM_eCS_TF_E_681; DOM_eCS_TF_E_683;DOM_eCS_TF_E_1976;DOM_eCS_TF_E_1978
      pseDID_FDE1_EcsParameters: provided-com-specs=[{operation=ReadData, queue-length=1}, {operation=WriteData, queue-length=1}], provided-interface=DataServices_DID_FDE1_EcsParametersData  # # Architecture Element ID ARCH_SW_DIA_pseDID_FDE1_EcsParameters_ReadData # Description - Interface shall be used to read the {eCS algorithm parameters} value from NVM and to save it in the {diagnostic buffer}. - {eCS algorithm parameters} shall have 49 bytes. # Data Flow ## Inputs: - {eCS algorithm parameters} ## Outputs - {diagnostic buffer} # Linked Runnable - DIA_runDidFDE1_EcsParametersRead # Traceability DOM_eCS_TF_E_323; DOM_eCS_TF_E_326; DOM_eCS_TF_E_329; DOM_eCS_TF_E_333; DOM_eCS_TF_E_337; DOM_eCS_TF_E_338; DOM_eCS_TF_E_339; DOM_eCS_TF_E_340; DOM_eCS_TF_E_341; DOM_eCS_TF_E_342; DOM_eCS_TF_E_343; DOM_eCS_TF_E_344; DOM_eCS_TF_E_345;DOM_eCS_TF_E_2266;DOM_eCS_TF_E_2267 # Architecture Element ID ARCH_SW_DIA_pseDID_FDE1_EcsParameters_WriteData # Description - Interface shall be used to write the {diagnostic buffer} value in NVP variable which stores the {eCS algorithm parameters}. - Interface shall return {ErrorCode} 0x22 if Ecu is locked. - Interface shall return {ErrorCode} 0x72 if the write operation failed. - {eCS algorithm parameters} shall have 49 bytes. # Data Flow ## Inputs: - {diagnostic buffer} ## Outputs - {eCS algorithm parameters} # Linked Runnable - DIA_runDidFDE1_EcsParametersWrite # Traceability DOM_eCS_TF_E_692; DOM_eCS_TF_E_694; DOM_eCS_TF_E_697; DOM_eCS_TF_E_700; DOM_eCS_TF_E_704; DOM_eCS_TF_E_708; DOM_eCS_TF_E_709; DOM_eCS_TF_E_710; DOM_eCS_TF_E_711; DOM_eCS_TF_E_712; DOM_eCS_TF_E_713; DOM_eCS_TF_E_714; DOM_eCS_TF_E_715;DOM_eCS_TF_E_716;DOM_eCS_TF_E_1979, DOM_eCS_TF_E_1981;DOM_eCS_TF_E_2268;DOM_eCS_TF_E_2269
      pseDID_FDE2_EcsAccOffsets: provided-com-specs=[{operation=ReadData, queue-length=1}, {operation=WriteData, queue-length=1}], provided-interface=DataServices_DID_FDE2_AccOffsetData  # # Architecture Element ID ARCH_SW_DIA_pseDID_FDE2_EcsAccOffsets_ReadData # Description - Interface shall be used to read {accelerometer offsets (x/y/z)} from NVM and to save it in the {diagnostic buffer}. - {accelerometer offsets (x/y/z)} shall have 6 bytes (2 for each axis). # Data Flow ## Inputs: - {accelerometer offsets (x/y/z)} ## Outputs - {diagnostic buffer} # Linked Runnable - DIA_runDidFDE2_EcsAccOffsetsRead # Traceability DOM_eCS_TF_E_354; DOM_eCS_TF_E_355; DOM_eCS_TF_E_356;DOM_eCS_TF_E_357 # Architecture Element ID ARCH_SW_DIA_pseDID_FDE2_EcsAccOffsets_WriteData # Description - Interface shall be used to write the {diagnostic buffer} value in the NVP variable which stores the {accelerometer offsets}. - Interface shall return {ErrorCode} 0x22 if Ecu is locked. - Interface shall return {ErrorCode} 0x72 if the write operation failed. - {accelerometer offsets} shall have 6 bytes. # Data Flow ## Inputs: - {diagnostic buffer} ## Outputs - {accelerometer offsets} # Linked Runnable - DIA_runDidFDE1_EcsParametersWrite # Traceability DOM_eCS_TF_E_725;DOM_eCS_TF_E_1982;DOM_eCS_TF_E_1984;DOM_eCS_TF_E_727;DOM_eCS_TF_E_728;DOM_eCS_TF_E_729;DOM_eCS_TF_E_1970
      pseDID_FDE3_EcsProfiles: provided-com-specs=[{operation=ReadData, queue-length=1}, {operation=WriteData, queue-length=1}], provided-interface=DataServices_DID_FDE3_EcsProfilesData  # # Architecture Element ID ARCH_SW_DIA_pseDID_FDE3_EcsProfiles_ReadData # Description - Interface shall be used to read the {eCS profiles} configuration from NVM and to save it in the {diagnostic buffer}. - {eCS profiles} configuration shall have n * 12 bytes. (n = 4). # Data Flow ## Inputs: - {eCS profiles} ## Outputs - {diagnostic buffer} # Linked Runnable - DIA_runDidFDE3_EcsProfilesRead # Traceability DOM_eCS_TF_E_377; DOM_eCS_TF_E_365;DOM_eCS_TF_E_2054;DOM_eCS_TF_E_2055 # Architecture Element ID ARCH_SW_DIA_pseDID_FDE3_EcsProfiles_WriteData # Description - Interface shall be used to write the {diagnostic bufer} configuration in the NVP variable which stores the {eCS profiles}. - Interface shall return {ErrorCode} 0x22 if Ecu is locked. - Interface shall return {ErrorCode} 0x72 if the write operation failed. - {eCS profiles} configuration shall have n * 12 bytes. (n = 4). # Data Flow ## Inputs: - {diagnostic buffer} ## Outputs - {eCS profiles} - {ErrorCode} # Linked Runnable - DIA_runDidFDE3_EcsProfilesWrite # Traceability DOM_eCS_TF_E_738; DOM_eCS_TF_E_740; DOM_eCS_TF_E_752;DOM_eCS_TF_E_1985;DOM_eCS_TF_E_1987
      pseDID_FDE4_EcsSteps: provided-com-specs=[{operation=ReadData, queue-length=1}, {operation=WriteData, queue-length=1}], provided-interface=DataServices_DID_FDE4_EcsStepsData  # # Architecture Element ID ARCH_SW_DIA_pseDID_FDE4_EcsSteps_ReadData # Description - Interface shall be used to read the {eCS steps} configuration from NVM and to save it in the {diagnostic buffer}. - {eCS steps} configuration shall have n * 7 bytes. (n = 8 steps). - first byte is duration MSB, second byte duration LSB, third byte is PWM order and forth byte is options. # Data Flow ## Inputs: - {eCS steps} ## Outputs - {diagnostic buffer} # Linked Runnable - DIA_runDidFDE4_EcsStepsRead # Traceability DOM_eCS_TF_E_397; DOM_eCS_TF_E_400; DOM_eCS_TF_E_403; DOM_eCS_TF_E_406; DOM_eCS_TF_E_409; DOM_eCS_TF_E_412; DOM_eCS_TF_E_415; DOM_eCS_TF_E_418; # Architecture Element ID ARCH_SW_DIA_pseDID_FDE4_EcsSteps_WriteData # Description - Interface shall be used to write the {diagnostic buffer} value in the NVP variable which store the {eCS steps}. - Interface shall return {ErrorCode} 0x22 if Ecu is locked. - Interface shall return {ErrorCode} 0x72 if the write operation failed. # Data Flow ## Inputs: - {diagnostic buffer} ## Outputs - {eCS steps} - {ErrorCode} # Linked Runnable - DIA_runDidFDE4_EcsStepsWrite # Traceability DOM_eCS_TF_E_772; DOM_eCS_TF_E_774; DOM_eCS_TF_E_777; DOM_eCS_TF_E_780; DOM_eCS_TF_E_783; DOM_eCS_TF_E_786; DOM_eCS_TF_E_789; DOM_eCS_TF_E_792; DOM_eCS_TF_E_795;DOM_eCS_TF_E_1988;DOM_eCS_TF_E_1990
      pseDID_FDE5_EcsAccLowPass: provided-com-specs=[{operation=ReadData, queue-length=1}, {operation=WriteData, queue-length=1}], provided-interface=DataServices_DID_FDE5_EcsAccLowPassData  # # Architecture Element ID ARCH_SW_DIA_pseDID_FDE5_EcsAccLowPass_ReadData # Description - Interface shall be used to read the {accelerometer lowpass filter value (x/y/z)} from NVM and to save it in the {diagnostic buffer}. - {accelerometer lowpass filter value (x/y/z)} shall have 3 bytes. # Data Flow ## Inputs: - {accelerometer lowpass filter value (x/y/z)} ## Outputs - {diagnostic buffer} # Linked Runnable - DIA_runDidFDE5_EcsAccLowPassRead # Traceability DOM_eCS_TF_E_429; DOM_eCS_TF_E_430; DOM_eCS_TF_E_431; # Architecture Element ID ARCH_SW_DIA_pseDID_FDE5_EcsAccLowPass_WriteData # Description - Interface shall be used to write the {diagnostic bufer} value in the NVP variable which stores the {accelerometer lowpass filter value (x/y/z)}. - Interface shall return {ErrorCode} 0x22 if Ecu is locked. - Interface shall return {ErrorCode} 0x72 if the write operation failed. - {accelerometer lowpass filter value (x/y/z)} shall have 3 bytes. # Data Flow ## Inputs: - {diagnostic buffer} ## Outputs - {accelerometer lowpass filter value (x/y/z)} # Linked Runnable - DIA_runDidFDE5_EcsAccLowPassWrite # Traceability DOM_eCS_TF_E_806; DOM_eCS_TF_E_808; DOM_eCS_TF_E_809; DOM_eCS_TF_E_810;DOM_eCS_TF_E_1991;DOM_eCS_TF_E_1993
      pseDID_FDE7_EcsAlgoOutputDelay: provided-com-specs=[{operation=ReadData, queue-length=1}, {operation=WriteData, queue-length=1}], provided-interface=DataServices_DID_FDE7_AlgoOutputDelayData  # # Architecture Element ID ARCH_SW_DIA_pseDID_FDE7_EcsAlgoOutputDelay_ReadData # Description - Interface shall be used to read {algo output delay} from NVM and to save it in the {diagnostic buffer}. - {algo output delay} shall have 2 bytes. # Data Flow ## Inputs: - {algo output delay} ## Outputs - {diagnostic buffer} # Linked Runnable - DIA_runDIDFDE7_EcsAlgoOutputDelayRead # Traceability DOM_eCS_TF_E_450; # Architecture Element ID ARCH_SW_DIA_pseDID_FDE7_EcsAlgoOutputDelay_WriteData # Description - Interface shall be used to write the {diagnostic buffer} value in the NVP variable which stores the {algo output delay}. - Interface shall return {ErrorCode} 0x22 if Ecu is locked. - Interface shall return {ErrorCode} 0x72 if the write operation failed. - {algo output delay} shall have 2 bytes. # Data Flow ## Inputs: - {algo output delay} ## Outputs - {diagnostic buffer} # Linked Runnable - DIA_runDIDFDE7_EcsAlgoOutputDelayWrite # Traceability DOM_eCS_TF_E_833; DOM_eCS_TF_E_835;DOM_eCS_TF_E_1994;DOM_eCS_TF_E_1996
      pseDID_FDE9_SensitivityLutData: provided-com-specs=[{operation=ReadData, queue-length=1}, {operation=WriteData, queue-length=1}], provided-interface=DataServices_DID_FDE9_SensitivityLutData  # # Architecture Element ID ARCH_SW_DIA_pseDID_FDE9_EcsSensitivityLut_ReadData # Description - Interface shall be used to read {eCS sensitivity lut} from NVM and to save it in the {diagnostic buffer}. - {eCS sensitivity lut} shall have 5 bytes. # Data Flow ## Inputs: - {eCS sensitivity lut} ## Outputs - {diagnostic buffer} # Linked Runnable - DIA_runDidFDE9_EcsSensitivityLutRead # Traceability DOM_eCS_TF_E_463; DOM_eCS_TF_E_468; # Architecture Element ID ARCH_SW_DIA_pseDID_FDE9_EcsSensitivityLut_WriteData # Description - Interface shall be used to write the {diagnostic buffer} value in the NVP variable which stores the {eCS sensitivity lut}. - Interface shall return {ErrorCode} 0x22 if Ecu is locked. - Interface shall return {ErrorCode} 0x72 if the write operation failed. - {eCS sensitivity lut} shall have 5 bytes. # Data Flow ## Inputs: - {diagnostic buffer} ## Outputs - {eCS sensitivity lut} # Linked Runnable - DIA_runDidFDE9_EcsSensitivityLutWrite # Traceability DOM_eCS_TF_E_844; DOM_eCS_TF_E_846; DOM_eCS_TF_E_851;DOM_eCS_TF_E_1997;DOM_eCS_TF_E_1999
      pseDID_FDEA_SensitivityOptData: provided-com-specs=[{operation=ReadData, queue-length=1}, {operation=WriteData, queue-length=1}], provided-interface=DataServices_DID_FDEA_SensitivityOptData  # # Architecture Element ID ARCH_SW_DIA_pseDID_FDEA_EcsSensitivityOpt_ReadData # Description - Interface shall be used to read the {accelerometer sensitivity optimization} value from NVM and to save it in the {diagnostic buffer}. # Data Flow ## Inputs: - {accelerometer sensitivity optimization} ## Outputs - {diagnostic buffer} # Linked Runnable - DIA_runDidFDEA_EcsSensitivityOptRead # Traceability DOM_eCS_TF_E_481; # Architecture Element ID ARCH_SW_DIA_pseDID_FDEA_EcsSensitivityOpt_WriteData # Description - Interface shall be used to write the {diagnostic buffer} value in NVP variable which stores the {accelerometer sensitivity optimization}. - Interface shall return {ErrorCode} 0x22 if Ecu is locked. - Interface shall return {ErrorCode} 0x72 if the write operation failed. - {accelerometer sensitivity optimization} shall have 1 byte. # Data Flow ## Inputs: - {diagnostic buffer} ## Outputs - {accelerometer sensitivity optimization} # Linked Runnable - DIA_runDidFDEA_EcsSensitivityOptWrite # Traceability DOM_eCS_TF_E_864; DOM_eCS_TF_E_866; DOM_eCS_TF_E_2000; DOM_eCS_TF_E_2002
      pseDID_FDFF_MeasurementFrameRamConf: provided-com-specs=[{operation=ReadData, queue-length=1}, {operation=WriteData, queue-length=1}], provided-interface=DataServices_DID_FDFF_MeasurementFrameConfDataRam  # # Architecture Element ID ARCH_SW_DIA_pseDID_FDFF_MeasurementFrameRamConf_ReadData # Description - Interface shall be used to read {measurement frame parameters from RAM} from NVM and to save it in the {diagnostic buffer}. # Data Flow ## Inputs: - {measurement frame parameters from RAM} ## Outputs - {diagnostic buffer} # Linked Runnable - DIA_runDidFDFF_MeasurementFrameRamConfRead # Traceability DOM_eCS_TF_E_2233;DOM_eCS_TF_E_2234;DOM_eCS_TF_E_2235;DOM_eCS_TF_E_2236;DOM_eCS_TF_E_2237;DOM_eCS_TF_E_2238;DOM_eCS_TF_E_2239;DOM_eCS_TF_E_2240;DOM_eCS_TF_E_2241;DOM_eCS_TF_E_2242;DOM_eCS_TF_E_2243;DOM_eCS_TF_E_2244;DOM_eCS_TF_E_2245;DOM_eCS_TF_E_2246;DOM_eCS_TF_E_2247;DOM_eCS_TF_E_2248;DOM_eCS_TF_E_2249;DOM_eCS_TF_E_2233DOM_eCS_TF_E_2249;DOM_eCS_TF_E_2250;DOM_eCS_TF_E_2251;DOM_eCS_TF_E_2252;DOM_eCS_TF_E_2253;DOM_eCS_TF_E_2254;DOM_eCS_TF_E_2255;DOM_eCS_TF_E_2256; DOM_eCS_TF_E_2257;DOM_eCS_TF_E_2258;DOM_eCS_TF_E_2259;DOM_eCS_TF_E_2260;DOM_eCS_TF_E_2261;DOM_eCS_TF_E_2262 # Architecture Element ID ARCH_SW_DIA_pseDID_FDFF_MeasurementFrameRamConf_WriteData # Description - Interface shall be used to write the {diagnostic buffer} value in the NVP variable which stores the {measurement frame parameters from RAM} from NVM and to save it in the {diagnostic buffer}. - Interface shall return {ErrorCode} 0x22 if Ecu is locked. - Interface shall return {ErrorCode} 0x72 if the write operation failed. # Data Flow ## Inputs: - {diagnostic buffer} ## Outputs - {measurement frame parameters from RAM} # Linked Runnable - DIA_runDidFDFF_MeasurementFrameRamConfWrite # Traceability DOM_eCS_TF_E_126;DOM_eCS_TF_E_2003;DOM_eCS_TF_E_2005;DOM_eCS_TF_E_2053;DOM_eCS_TF_E_2203;DOM_eCS_TF_E_2204;DOM_eCS_TF_E_2205;DOM_eCS_TF_E_2206;DOM_eCS_TF_E_2207;DOM_eCS_TF_E_2208;DOM_eCS_TF_E_2209;DOM_eCS_TF_E_2210;DOM_eCS_TF_E_2211;DOM_eCS_TF_E_2212;DOM_eCS_TF_E_2213;DOM_eCS_TF_E_2214;DOM_eCS_TF_E_2215;DOM_eCS_TF_E_2216;DOM_eCS_TF_E_2217;DOM_eCS_TF_E_2218;DOM_eCS_TF_E_2219;DOM_eCS_TF_E_2220;DOM_eCS_TF_E_2221;DOM_eCS_TF_E_2222;DOM_eCS_TF_E_2223; DOM_eCS_TF_E_2224;DOM_eCS_TF_E_2225;DOM_eCS_TF_E_2226;DOM_eCS_TF_E_2227;DOM_eCS_TF_E_2228;DOM_eCS_TF_E_2229;DOM_eCS_TF_E_2230;DOM_eCS_TF_E_2231;
      pseDID_FE00_AllEventStatusesRead: server-com-spec{operation=ReadData, queue-length=1}, provided-interface=DataServices_DID_FE00_AllEventStatusesRead  # # Architecture Element ID ARCH_SW_DIA_pseDID_FE00_AllEventStatusesRead # Description - Interface shall be used to read {DEM events status} and to save it in the {diagnostic buffer}. - {DEM events status} shall have n * 3 bytes (n = number of events). # Data Flow ## Inputs: - {DEM events status} ## Outputs - {diagnostic buffer} # Linked Runnable - DIA_runDidFE00_AllEventStatusesRead # Traceability DOM_eCS_TF_E_262; DOM_eCS_TF_E_263; DOM_eCS_TF_E_264; DOM_eCS_TF_E_265; DOM_eCS_TF_E_266; DOM_eCS_TF_E_267; DOM_eCS_TF_E_268; DOM_eCS_TF_E_269; DOM_eCS_TF_E_270; DOM_eCS_TF_E_271; DOM_eCS_TF_E_272; DOM_eCS_TF_E_273; DOM_eCS_TF_E_274; DOM_eCS_TF_E_275; DOM_eCS_TF_E_276; DOM_eCS_TF_E_277; DOM_eCS_TF_E_278; DOM_eCS_TF_E_279; DOM_eCS_TF_E_280; DOM_eCS_TF_E_281; DOM_eCS_TF_E_282; DOM_eCS_TF_E_283; DOM_eCS_TF_E_284; DOM_eCS_TF_E_285; DOM_eCS_TF_E_286; DOM_eCS_TF_E_287; DOM_eCS_TF_E_2087;DOM_eCS_TF_E_2088;DOM_eCS_TF_E_2089;DOM_eCS_TF_E_2090;DOM_eCS_TF_E_2091;DOM_eCS_TF_E_2092;DOM_eCS_TF_E_2093;DOM_eCS_TF_E_2094;DOM_eCS_TF_E_2095;DOM_eCS_TF_E_2096;DOM_eCS_TF_E_2097;DOM_eCS_TF_E_2098;DOM_eCS_TF_E_2099;DOM_eCS_TF_E_2100;DOM_eCS_TF_E_2101;DOM_eCS_TF_E_2102;DOM_eCS_TF_E_2103;DOM_eCS_TF_E_2104;DOM_eCS_TF_E_2264;DOM_eCS_TF_E_2265
      pseDID_FEFF_MeasurementFramesConf: provided-com-specs=[{operation=ReadData, queue-length=1}, {operation=WriteData, queue-length=1}], provided-interface=DataServices_DID_FEFF_MeasurementFramesConfData  # # Architecture Element ID ARCH_SW_DIA_pseDID_FEFF_MeasurementFramesConf_ReadData # Description - Interface shall be used to read the {Measurement Frames parameters} from NVM and to save it in the {diagnostic buffer}. - {Measurement Frames parameters} shall have 5 bytes. # Data Flow ## Inputs: - {Measurement Frames parameters} ## Outputs - {diagnostic buffer} # Linked Runnable - DIA_runDidFEFF_MeasurementFramesConfRead # Traceability DOM_eCS_TF_E_166; DOM_eCS_TF_E_167; DOM_eCS_TF_E_168; # Architecture Element ID ARCH_SW_DIA_pseDID_FEFF_MeasurementFramesConf_WriteData # Description - Interface shall be used to write the {diagnostic buffer} value in the NVP variable which stores the {Measurement Frames parameters}. - Interface shall return {ErrorCode} 0x22 if Ecu is locked. - Interface shall return {ErrorCode} 0x72 if the write operation failed. - {Measurement Frames parameters} shall have 5 bytes. # Data Flow ## Inputs: - {diagnostic buffer} ## Outputs - {Measurement Frames parameters} # Linked Runnable - DIA_runDidFEFF_MeasurementFramesConfWrite # Traceability DOM_eCS_TF_E_653; DOM_eCS_TF_E_655; DOM_eCS_TF_E_656; DOM_eCS_TF_E_657; DOM_eCS_TF_E_658; DOM_eCS_TF_E_659;DOM_eCS_TF_E_2006;DOM_eCS_TF_E_2008
      pseEcsDiagRequest: provided-interface=isrEcsDiagRequest  # pseEcsDiagnosticRequest | # Architecture Element ID ARCH_SW_DIA_pseEcsDiagRequest # Description - Interface shall be used to send the {diagnostic lock/unlock request} to set solenoid in lock or unlock. # Data Flow ## Inputs: ## Outputs - {diagnostic lock/unlock request} # Linked Runnable - DIA_runRidF795_LockSolenoidStart - DIA_runRidF795_LockSolenoidStop # Traceability
        provided-com-specs:
          data-element=au8DiagReq, uses-end-to-end-protection=0, init-value=6 x KU8_NO_DIAG_REQUEST
          data-element=au8DiagReqComplement, uses-end-to-end-protection=0, init-value=6 x KU8_NO_DIAG_REQUEST_COMPLEMENT
    require port pseNvpBlockData: required-com-specs=[u8NvpProcessMode, u8NvpEcuLockStatus], required-interface=nvNvpBlockDescriptor  # # Architecture Element ID ARCH_SW_DIA_pseNvpBlockData_ProcessModeRequestRes # Description - Interface shall be used to read the {process mode status}. # Data Flow ## Inputs: ## Outputs - {process mode status} # Linked Runnable - DIA_runRidF793_ProcessModeRequestRes # Traceability # Architecture Element ID ARCH_SW_DIA_pseNvpBlockData_ECULockStatus # Description - Interface shall be used to read the {Ecu lock status}. # Data Flow ## Inputs: - {Ecu lock status} ## Outputs # Linked Runnable - DIA_runRidF781_EcuUnlockRequestRes # Traceability
    10 x provide port:
      pseRoutineControl_AccAngleOffsetCalibration: server-com-spec{operation=Start, queue-length=1}, provided-interface=RoutineServices_DcmDspRoutineAccAngleOffsetCalibration  # # Architecture Element ID ARCH_SW_DIA_pseRoutineControl_AccAngleOffsetCalibration # Description - Interface shall be used to compute the {XAxisAngleCalib, YAxisAngleCalib, ZAxisAngleCalib} values based on {XAxisAngle, YAxisAngle, ZAxisAngle} values. - Interface shall be used to write the {XAxisAngleCalib, YAxisAngleCalib, ZAxisAngleCalib} in NVP variables. - Interface shall be used to start the ACC Angle Offset Calibration. - Interface shall response with {routine info byte}. - Interface shall return {ErrorCode} 0x22 if Ecu is locked. - Interface shall return {ErrorCode} 0x72 if the write operation failed. - {XAxisAngleCalib, YAxisAngleCalib, ZAxisAngleCalib} shall have 6 bytes ( 3 * 2 bytes). # Data Flow ## Inputs: - {XAxisAngle, YAxisAngle, ZAxisAngle} ## Outputs - {XAxisAngleCalib, YAxisAngleCalib, ZAxisAngleCalib} - {routine info byte} - {ErrorCode} # Linked Runnable - DIA_runRidF797_AccAngleOffsetCalibrationStart # Traceability DOM_eCS_TF_E_156;DOM_eCS_TF_E_157;DOM_eCS_TF_E_197;DOM_eCS_TF_E_201;DOM_eCS_TF_E_150
      pseRoutineControl_AccCalib: server-com-spec{operation=Start, queue-length=1}, provided-interface=RoutineServices_DcmDspRoutineAccCalib  # # Architecture Element ID ARCH_SW_DIA_pseRoutineControl_AccCalib # Description - Interface shall be used to compute {OffsetAx, OffsetAy, OffsetAz} based on {raw acceleration in g}. - Interface shall be used to start the the accelerometer calibration. - Interface shall return the {routine info byte}. - Interface shall return {ErrorCode} 0x22 if Ecu is locked. - Interface shall return {ErrorCode} 0x72 if the write operation failed. # Data Flow ## Inputs: - {raw acceleration in g} ## Outputs - {OffsetAx, OffsetAy, OffsetAz} - {routine info byte} - {ErrorCode} # Linked Runnable - DIA_runRidF794_AccCalibStart # Traceability DOM_eCS_TF_E_1229;DOM_eCS_TF_E_204;DOM_eCS_TF_E_1240;DOM_eCS_TF_E_1244
      pseRoutineControl_CheckProgrammingPreconditions: server-com-spec{operation=Start, queue-length=1}, provided-interface=RoutineServices_DcmDspRoutineRoutineCheckProgrammingPreconditions  # # Architecture Element ID ARCH_SW_DIA_pseRoutineControl_CheckProgrammingPreconditions # Description - Interface shall be used to check if any {DEM Events} occurs and to write {programming preconditions} on diagnostic buffer. - Interface shall return the {routine info byte}. # Data Flow ## Inputs: - {DEM Events} ## Outputs - {programming preconditions} - {routine info byte} # Linked Runnable - DIA_runRid0203_CheckProgrammingPreconditions # Traceability DOM_eCS_TF_E_1880, DOM_eCS_TF_E_1881, DOM_eCS_TF_E_1882, DOM_eCS_TF_E_1918
      pseRoutineControl_EcuTempCalibration: server-com-spec{operation=Start, queue-length=1}, provided-interface=RoutineServices_DcmDspRoutineEcuTempCalibration  # # Architecture Element ID ARCH_SW_DIA_pseRoutineControl_EcuTempCalibration # Description - Interface shall be used to compute the {McuTempOffset, AccTempOffset, PtcTempOffset} values based on {McuTemperature, ACCTemperature, PtcSensorTemperature, EnvironmentalTemperature} values. - Interface shall be used to write the {McuTempOffset, AccTempOffset, PtcTempOffset} in NVP variables. - Interface shall be used to start the Ecu Temperature Calibration. - Interface shall response with {routine info byte}. - Interface shall return {ErrorCode} 0x22 if Ecu is locked. - {McuTempOffset, AccTempOffset, PtcTempOffset} shall have 3 bytes. # Data Flow ## Inputs: - {McuTemperature, ACCTemperature, PtcSensorTemperature, EnvironmentalTemperature} ## Outputs - {McuTempOffset, AccTempOffset, PtcTempOffset} - {routine info byte} - {Error Code} # Linked Runnable - DIA_runRidF796_EcuTempCalibration # Traceability DOM_eCS_TF_E_1269;DOM_eCS_TF_E_1274;DOM_eCS_TF_E_1431,DOM_eCS_TF_E_1279;DOM_eCS_TF_E_1283
      pseRoutineControl_LockSolenoid: provided-com-specs=[{operation=Start, queue-length=1}, {operation=Stop, queue-length=1}], provided-interface=RoutineServices_DcmDspRoutineLockSolenoid  # # Architecture Element ID ARCH_SW_DIA_pseRoutineControl_LockSolenoid_Start # Description - Interface shall be used to send the {diagnostic request} to the eCS module to set solenoids in {lock state} based on {lock/unlock solenoids status}. - Interface shall return the {routine info byte}. # Data Flow ## Inputs: - {diagnostic request} - {lock/unlock solenoids status} ## Outputs - {lock action} - {routine info byte} # Linked Runnable - DIA_runRidF795_LockSolenoidStart # Traceability DOM_eCS_TF_E_205; DOM_eCS_TF_R_27 # Architecture Element ID ARCH_SW_DIA_pseRoutineControl_LockSolenoid_Stop # Description - Interface shall be used to send the {diagnostic request} to {clear lock state} based on {unlock solenoids status}. - Interface shall return the {routine info byte}. # Data Flow ## Inputs: - {diagnostic request} - {lock/unlock solenoids status} ## Outputs - {clear lock state} - {routine info byte} # Linked Runnable - DIA_runRidF795_LockSolenoidStop # Traceability DOM_eCS_TF_E_205;
      pseRoutineControl_LockUnlockECU: provided-interface=RoutineServices_DcmDspRoutineCtrl_Lock_UnlockECU  # # Architecture Element ID ARCH_SW_DIA_pseRoutineControl_LockUnlockECU_Start # Description - Interface shall be used to send the {diagnostic request} to the eCS module to {unlock the Ecu}. - Interface shall return the {routine info byte}. - Interface shall return {ErrorCode} 0x72 if the clear data block index or the send request failed. # Data Flow ## Inputs: - {diagnostic request} ## Outputs - {unlock the Ecu} - {ErrorCode} # Linked Runnable - DIA_runRidF781_EcuUnlockStart # Traceability DOM_eCS_TF_E_1336; DOM_eCS_TF_E_1335;DOM_eCS_TF_E_202;DOM_eCS_TF_E_1204 # Architecture Element ID ARCH_SW_DIA_pseRoutineControl_LockUnlockECU_Stop # Description - Interface shall be used to send the {diagnostic request} to the eCS module to {lock the Ecu}. - Interface shall return the {routine info byte}. - Interface shall return {ErrorCode} 0x72 if the clear data block index or the send request failed. # Data Flow ## Inputs: - {diagnostic request} ## Outputs - {lock the Ecu} - {ErrorCode} # Linked Runnable - DIA_runRidF781_EcuUnlockStop # Traceability DOM_eCS_TF_E_202 # Architecture Element ID ARCH_SW_DIA_pseRoutineControl_LockUnlockECU_RequestResult # Description - Interface used to read the ECU lock/unlock status. # Data Flow ## Inputs: ## Outputs - ECU lock/unlock status # Linked Runnable - DIA_runRidF781_EcuUnlockRequestRes # Traceability
        provided-com-specs:
          operation=Start, queue-length=1
          operation=Stop, queue-length=1
          operation=RequestResults, queue-length=1
      pseRoutineControl_ProcessModeRoutine: provided-interface=RoutineServices_DcmDspRoutineProcessMode  # # Architecture Element ID ARCH_SW_DIA_pseRoutineControl_ProcessMode_Start # Description - Interface shall be used to send the {diagnostic request} to the eCS module to {start the process mode}. - Interface shall be used to write the {process mode status} in the NVP variable which stores the process mode in the {diagnostic buffer}. - Interface shall return the {routine info byte}. - Interface shall return {ErrorCode} 0x22 if Ecu is locked. - Interface shall return {ErrorCode} 0x72 if the write operation failed. # Data Flow ## Inputs: - {diagnostic request} - {process mode status} ## Outputs - {start the process mode} - {routine info byte} - {ErrorCode} # Linked Runnable - DIA_runRidF793_ProcessModeStart # Traceability DOM_eCS_TF_P_175; DOM_eCS_TF_E_1223; DOM_eCS_TF_E_1337; DOM_eCS_TF_E_1338; DOM_eCS_TF_E_1224;DOM_eCS_TF_E_203;DOM_eCS_TF_E_1339;DOM_eCS_TF_E_1339;DOM_eCS_TF_E_1222 # Architecture Element ID ARCH_SW_DIA_pseRoutineControl_ProcessMode_Stop # Description - Interface shall be used to send the {diagnostic request} to the eCS module to {stop the process mode}. - Interface shall be used to write the NVP variable which stores the process mode in the {diagnostic buffer}. - Interface shall return the {routine info byte}. - Interface shall return {ErrorCode} 0x22 if Ecu is locked. - Interface shall return {ErrorCode} 0x72 if the write operation failed. # Data Flow ## Inputs: - {diagnostic request} ## Outputs - {stop the process mode} - {routine info byte} - {ErrorCode} # Linked Runnable - DIA_runRidF793_ProcessModeStop # Traceability DOM_eCS_TF_P_187; DOM_eCS_TF_E_1223;DOM_eCS_TF_E_203;DOM_eCS_TF_E_1222 # Architecture Element ID ARCH_SW_DIA_pseRoutineControl_ProcessMode_RequestRes # Description - Interface shall be used to read the {process mode state} and to return the {process mode status}. - Interface shall return {routine info byte}. # Data Flow ## Inputs: - {process mode state} ## Outputs - {process mode status} - {routine info byte} # Linked Runnable - DIA_runRidF793_ProcessModeRequestRes # Traceability DOM_eCS_TF_E_1223;
        provided-com-specs:
          operation=RequestResults, queue-length=1
          operation=Start, queue-length=1
          operation=Stop, queue-length=1
      pseSecurityAccess: provided-com-specs=[{operation=GetSeed, queue-length=1}, {operation=CompareKey, queue-length=1}], provided-interface=SecurityAccess_DcmDspSecurityAlv  # # Architecture Element ID ARCH_SW_DIA_pseSecurityAccess_GetSeed # Description - Interface used to generate a {seed} which will be sent to the tester. Based on it, the tester will compute the security access key. # Data Flow ## Inputs: ## Outputs - {seed} # Linked Runnable - DIA_runSecurityAccessGetSeed # Traceability # Architecture Element ID ARCH_SW_DIA_pseSecurityAccess_CompareKey # Description - Interface used to check that the {key} computed by the tester tool match the expected one, the key computed during last execution of DIA_runSecurityAccessGetSeed service. - Interface shall return {Error Code} 0x35 if the received key is invalid. # Data Flow ## Inputs: - {key} ## Outputs - {Error Code} # Linked Runnable - ARCH_SW_DIA_pseSecurityAccess_CompareKey # Traceability
      pseServiceRequestSupplierNotification: provided-com-specs=[{operation=Indication, queue-length=1}, {operation=Confirmation, queue-length=1}], provided-interface=ServiceRequestNotification  # # Architecture Element ID ARCH_SW_DIA_pseServiceRequestSupplierNotification_Indication # Description - Interface provide service request supplier notification indication. # Data Flow ## Inputs: - {SID, request data, data size, request type, source address} ## Outputs - {indication status} # Linked Runnable - DIA_runServiceRequestIndication # Traceability # Architecture Element ID ARCH_SW_DIA_pseServiceRequestSupplierNotification_Confirmation # Description - Interface provide service request supplier notification confirmation # Data Flow ## Inputs: - {SID, request type, source address} ## Outputs - {confirmation status} # Linked Runnable - DIA_runServiceRequestConfirmation # Traceability
      ptrpDiaServicesBswMIf: provided-interface=itrDiaServices  # # Architecture Element ID ARCH_SW_Dia_ptrpDiaServicesBswMIf_DIA_Init # Description - The DIA_Init runnable shall be called during the initialization in the BswM_OnStartComEffective runnable # Data Flow # Linked Runnable - DIA_Init # Traceability
